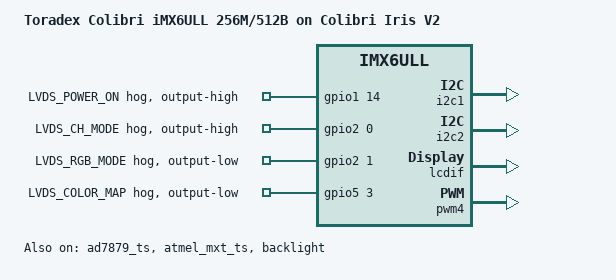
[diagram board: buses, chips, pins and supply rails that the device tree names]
/dts-v1/;
#include "imx6ull-colibri-nonwifi.dtsi"
#include "imx6ull-colibri-iris-v2.dtsi"
/ {
	model = "Toradex Colibri iMX6ULL 256M/512B on Colibri Iris V2";
	compatible = "toradex,colibri-imx6ull-iris-v2",
		     "toradex,colibri-imx6ull",
		     "fsl,imx6ull";
};
&ad7879_ts {
	status = "okay";
};
&atmel_mxt_ts {
	status = "okay";
};
&backlight {
	status = "okay";
};
&gpio1 {
	lvds-power-on-hog {
		gpio-hog;
		gpios = <14 GPIO_ACTIVE_HIGH>;  
		line-name = "LVDS_POWER_ON";
		output-high;
	};
};
&gpio2 {
	lvds-ch-mode-hog {
		gpio-hog;
		gpios = <0 GPIO_ACTIVE_HIGH>;  
		line-name = "LVDS_CH_MODE";
		output-high;
	};
	lvds-rgb-mode-hog {
		gpio-hog;
		gpios = <1 GPIO_ACTIVE_HIGH>;  
		line-name = "LVDS_RGB_MODE";
		output-low;
	};
};
&gpio5 {
	lvds-color-map-hog {
		gpio-hog;
		gpios = <3 GPIO_ACTIVE_HIGH>;  
		line-name = "LVDS_COLOR_MAP";
		output-low;
	};
};
&i2c1 {
	status = "okay";
};
&i2c2 {
	status = "okay";
};
&lcdif {
	status = "okay";
};
&panel_dpi {
	status = "okay";
};
&pwm4 {
	status = "okay";
};
&pwm5 {
	status = "disabled";
};
&pwm6 {
	status = "disabled";
};
